VERSION ""

NS_ :

BS_:

BU_:
VAL_TABLE_ FMI 22 "Data Drifted Low" 21 "Data Drifted High" 20 "Received Network Data In Error" 0 "Above normal (most severe)" 1 "Below normal (most severe)" 2 "Data erratic" 3 "Voltage above normal" 4 "Voltage below normal" 5 "Current below normal" 6 "Current above normal" 7 "Mechanical system not responding" 8 "Abnormal frequency" 9 "Abnormal update rate" 10 "Abnormal rate of change" 11 "Root cause not known" 12 "Bad intelligent device" 13 "Out of calibration" 14 "Special intstructions" 15 "Above normal (least severe)" 16 "Above normal (moderately severe)" 17 "Below normal (least severe)" 18 "Below normal (moderately severe)" 19 "Received network data in error" 31 "Condition Exists" ;

BO_ 2381860606 LGTSLVL2HMI: 1 Vector__XXX
 SG_ HeadLampActualLevel : 2|3@1+ (1,0) [0|7] "" Vector__XXX
 SG_ HeadlampLvlMode : 0|2@1+ (1,0) [0|3] "" Vector__XXX

BO_ 2381859838 ELS2HMI_Sts: 1 Vector__XXX
 SG_ AutoLowBeamSts : 0|2@1+ (1,0) [0|3] "" Vector__XXX

BO_ 2381859582 HMI2ELS_Req: 1 Vector__XXX
 SG_ AutoLowBeamReq : 0|2@1+ (1,0) [0|3] "" Vector__XXX

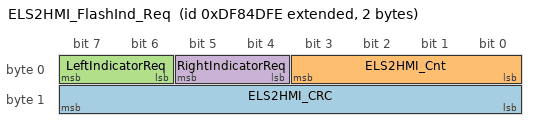
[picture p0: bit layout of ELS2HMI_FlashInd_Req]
BO_ 2381860350 ELS2HMI_FlashInd_Req: 2 Vector__XXX
 SG_ ELS2HMI_CRC : 8|8@1+ (1,0) [0|0] "" Vector__XXX
 SG_ ELS2HMI_Cnt : 0|4@1+ (1,0) [0|0] "" Vector__XXX
 SG_ LeftIndicatorReq : 6|2@1+ (1,0) [0|3] "" Vector__XXX
 SG_ RightIndicatorReq : 4|2@1+ (1,0) [0|3] "" Vector__XXX

CM_ "$File: //depot/auto/dbc/Software_Modules/Exterior_Lights/HMI_ELS/0.1.6.0/HMI_ELS.dbc $
$Change: 215976 $
$DateTime: 2024/08/21 10:06:15 $
$Revision: #1 $";
CM_ BO_ 2381860606 "Requests from HMI to ELS";
CM_ BO_ 2381859838 "Status of ELS to HMI";
CM_ SG_ 2381859838 AutoLowBeamSts "This parameter provides auto low beam state";
CM_ BO_ 2381859582 "Requests from HMI to ELS";
CM_ SG_ 2381859582 AutoLowBeamReq "Request to activate auto low beam operation";
BA_DEF_  "DBName" STRING ;
BA_DEF_ SG_  "SigType" ENUM  "Default","Range","RangeSigned","ASCII","Discrete","Control","ReferencePGN","DTC","StringDelimiter","StringLength","StringLengthControl","MessageCounter","MessageChecksum";
BA_DEF_ SG_  "GenSigSendType" ENUM  "Cyclic","OnWrite","OnWriteWithRepetition","OnChange","OnChangeWithRepetition","IfActive","IfActiveWithRepetition","NoSigSendType";
BA_DEF_ SG_  "GenSigILSupport" ENUM  "No","Yes";
BA_DEF_ SG_  "GenSigEVName" STRING ;
BA_DEF_ BO_  "GenMsgILSupport" ENUM  "No","Yes";
BA_DEF_ BO_  "GenMsgDelayTime" INT 0 1000;
BA_DEF_ BO_  "GenMsgRequestable" INT 0 1;
BA_DEF_ BO_  "GenMsgSendType" ENUM  "cyclic","NotUsed","NotUsed","NotUsed","NotUsed","NotUsed","NotUsed","IfActive","noMsgSendType";
BA_DEF_ BO_  "VFrameFormat" ENUM  "StandardCAN","ExtendedCAN","reserved","J1939PG";
BA_DEF_ BO_  "GenMsgCycleTime" INT 0 3600000;
BA_DEF_ BO_  "SendOnChange" ENUM  "No","Yes";
BA_DEF_ BU_  "NmStationAddress" INT 0 255;
BA_DEF_  "SAE_J1939_DA_SpecVersion" STRING ;
BA_DEF_  "SAE_J1939_81_SpecVersion" STRING ;
BA_DEF_  "DatabaseVersion" STRING ;
BA_DEF_  "BusType" STRING ;
BA_DEF_  "ProtocolType" STRING ;
BA_DEF_  "SAE_J1939_75_SpecVersion" STRING ;
BA_DEF_  "SAE_J1939_21_SpecVersion" STRING ;
BA_DEF_  "SAE_J1939_73_SpecVersion" STRING ;
BA_DEF_  "SAE_J1939_71_SpecVersion" STRING ;
BA_DEF_ BO_  "Producer" STRING ;
BA_DEF_DEF_  "DBName" "";
BA_DEF_DEF_  "SigType" "Default";
BA_DEF_DEF_  "GenSigSendType" "NoSigSendType";
BA_DEF_DEF_  "GenSigILSupport" "Yes";
BA_DEF_DEF_  "GenSigEVName" "Env@Nodename_@Signame";
BA_DEF_DEF_  "GenMsgILSupport" "Yes";
BA_DEF_DEF_  "GenMsgDelayTime" 0;
BA_DEF_DEF_  "GenMsgRequestable" 1;
BA_DEF_DEF_  "GenMsgSendType" "noMsgSendType";
BA_DEF_DEF_  "VFrameFormat" "J1939PG";
BA_DEF_DEF_  "GenMsgCycleTime" 0;
BA_DEF_DEF_  "SendOnChange" "No";
BA_DEF_DEF_  "NmStationAddress" 254;
BA_DEF_DEF_  "SAE_J1939_DA_SpecVersion" "";
BA_DEF_DEF_  "SAE_J1939_81_SpecVersion" "";
BA_DEF_DEF_  "DatabaseVersion" "";
BA_DEF_DEF_  "BusType" "";
BA_DEF_DEF_  "ProtocolType" "";
BA_DEF_DEF_  "SAE_J1939_75_SpecVersion" "";
BA_DEF_DEF_  "SAE_J1939_21_SpecVersion" "";
BA_DEF_DEF_  "SAE_J1939_73_SpecVersion" "";
BA_DEF_DEF_  "SAE_J1939_71_SpecVersion" "";
BA_ "SAE_J1939_71_SpecVersion" "2012-10";
BA_ "SAE_J1939_73_SpecVersion" "2012-10";
BA_ "SAE_J1939_21_SpecVersion" "2006-10";
BA_ "SAE_J1939_75_SpecVersion" "2012-05";
BA_ "ProtocolType" "J1939";
BA_ "BusType" "CAN";
BA_ "DatabaseVersion" "8.5";
BA_ "SAE_J1939_81_SpecVersion" "2012-05";
BA_ "SAE_J1939_DA_SpecVersion" "2015-01";
BA_ "DBName" "HMI_ELS";
BA_ "SendOnChange" BO_ 2381860606 1;
BA_ "GenMsgCycleTime" BO_ 2381860606 1000;
BA_ "GenMsgSendType" BO_ 2381860606 0;
BA_ "GenMsgDelayTime" BO_ 2381860606 100;
BA_ "SendOnChange" BO_ 2381859838 1;
BA_ "GenMsgCycleTime" BO_ 2381859838 1000;
BA_ "GenMsgSendType" BO_ 2381859838 0;
BA_ "GenMsgDelayTime" BO_ 2381859838 100;
BA_ "SendOnChange" BO_ 2381859582 1;
BA_ "GenMsgCycleTime" BO_ 2381859582 1000;
BA_ "GenMsgSendType" BO_ 2381859582 0;
BA_ "GenMsgDelayTime" BO_ 2381859582 100;
BA_ "GenMsgDelayTime" BO_ 2381860350 100;
BA_ "GenMsgSendType" BO_ 2381860350 0;
BA_ "GenMsgCycleTime" BO_ 2381860350 1000;
BA_ "SendOnChange" BO_ 2381860350 1;
BA_ "SigType" SG_ 2381860350 ELS2HMI_CRC 12;
BA_ "SigType" SG_ 2381860350 ELS2HMI_Cnt 11;
BA_ "Producer" BO_ 2381860606 "ELS";
BA_ "Producer" BO_ 2381859838 "ELS";
BA_ "Producer" BO_ 2381860350 "ELS";
VAL_ 2381860606 HeadLampActualLevel 7 "Not_Available" 6 "Error" 2 "High_level" 1 "Normal_level" 0 "Low_level" ;
VAL_ 2381860606 HeadlampLvlMode 3 "Not_Available" 2 "Error" 1 "Manual_Mode" 0 "Auto_Mode" ;
VAL_ 2381859838 AutoLowBeamSts 3 "Not Available" 2 "Fault Detected" 1 "AutoSelected" 0 "AutoNotSelected" ;
VAL_ 2381859582 AutoLowBeamReq 3 "Don't Care" 2 "Reserved" 1 "AutoRequested" 0 "AutoNotRequested" ;
VAL_ 2381860350 LeftIndicatorReq 3 "Don_t_Care" 2 "Error" 1 "Activated" 0 "De_activated" ;
VAL_ 2381860350 RightIndicatorReq 3 "Don_t_Care" 2 "Error" 1 "Activated" 0 "De_activated" ;
